VERSION ""

NS_ :

BS_:

BU_: XXX

BO_ 380 ENGINE: 8 XXX
 SG_ NEW_SIGNAL_2 : 61|2@0+ (1,0) [0|3] "" XXX
 SG_ ENGINE_RPM : 23|16@0+ (1,0) [0|255] "" XXX

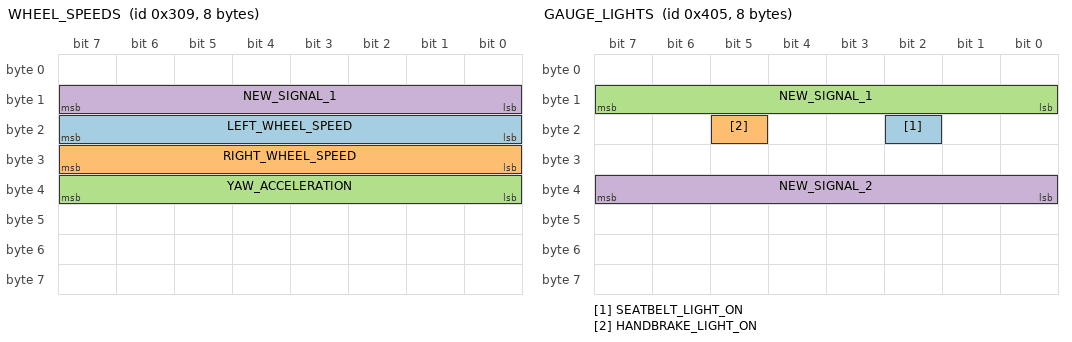
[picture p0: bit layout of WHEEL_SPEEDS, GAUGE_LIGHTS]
BO_ 777 WHEEL_SPEEDS: 8 XXX
 SG_ LEFT_WHEEL_SPEED : 23|8@0+ (1,0) [0|255] "" XXX
 SG_ RIGHT_WHEEL_SPEED : 31|8@0+ (1,0) [0|255] "" XXX
 SG_ YAW_ACCELERATION : 39|8@0+ (1,0) [0|255] "" XXX
 SG_ NEW_SIGNAL_1 : 15|8@0+ (1,0) [0|255] "" XXX

BO_ 398 NEW_MSG_2: 8 XXX
 SG_ NEW_SIGNAL_1 : 14|7@0+ (1,0) [0|255] "" XXX
 SG_ NEW_SIGNAL_2 : 21|6@0+ (1,0) [0|255] "" XXX

BO_ 1029 GAUGE_LIGHTS: 8 XXX
 SG_ SEATBELT_LIGHT_ON : 18|1@0+ (1,0) [0|255] "" XXX
 SG_ HANDBRAKE_LIGHT_ON : 21|1@0+ (1,0) [0|3] "" XXX
 SG_ NEW_SIGNAL_1 : 15|8@0+ (1,0) [0|255] "" XXX
 SG_ NEW_SIGNAL_2 : 39|8@0+ (1,0) [0|255] "" XXX

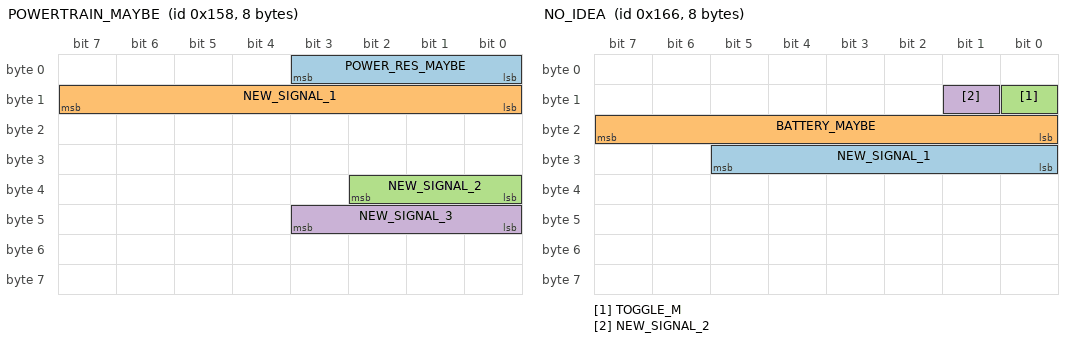
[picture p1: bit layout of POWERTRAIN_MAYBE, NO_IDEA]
BO_ 344 POWERTRAIN_MAYBE: 8 XXX
 SG_ POWER_RES_MAYBE : 0|4@1+ (1,0) [0|15] "" XXX
 SG_ NEW_SIGNAL_1 : 15|8@0+ (1,0) [0|255] "" XXX
 SG_ NEW_SIGNAL_2 : 32|3@1+ (1,0) [0|7] "" XXX
 SG_ NEW_SIGNAL_3 : 43|4@0+ (1,0) [0|255] "" XXX

BO_ 358 NO_IDEA: 8 XXX
 SG_ NEW_SIGNAL_1 : 29|6@0+ (1,0) [0|63] "" XXX
 SG_ BATTERY_MAYBE : 23|8@0+ (1,0) [0|255] "" XXX
 SG_ TOGGLE_M : 8|1@0+ (1,0) [0|255] "" XXX
 SG_ NEW_SIGNAL_2 : 9|1@1+ (1,0) [0|3] "" XXX

BO_ 401 NEW_MSG_1: 8 XXX
 SG_ NEW_SIGNAL_1 : 16|2@1+ (1,0) [0|3] "" XXX
 SG_ NEW_SIGNAL_2 : 55|8@0+ (1,0) [0|255] "" XXX

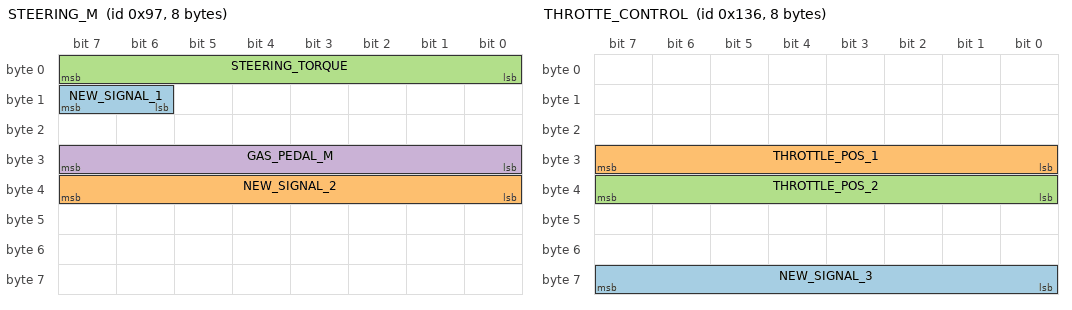
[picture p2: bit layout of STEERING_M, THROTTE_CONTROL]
BO_ 151 STEERING_M: 8 XXX
 SG_ NEW_SIGNAL_1 : 15|2@0+ (1,0) [0|255] "" XXX
 SG_ NEW_SIGNAL_2 : 39|8@0+ (1,0) [0|255] "" XXX
 SG_ STEERING_TORQUE : 7|8@0+ (1,0) [0|255] "" XXX
 SG_ GAS_PEDAL_M : 31|8@0+ (1,0) [0|255] "" XXX

BO_ 310 THROTTE_CONTROL: 8 XXX
 SG_ NEW_SIGNAL_3 : 63|8@0+ (1,0) [0|255] "" XXX
 SG_ THROTTLE_POS_1 : 31|8@0+ (1,0) [0|255] "" XXX
 SG_ THROTTLE_POS_2 : 39|8@0+ (1,0) [0|255] "" XXX

BO_ 57 NEW_MSG_3: 8 XXX
 SG_ NEW_SIGNAL_1 : 15|8@0+ (1,0) [0|255] "" XXX

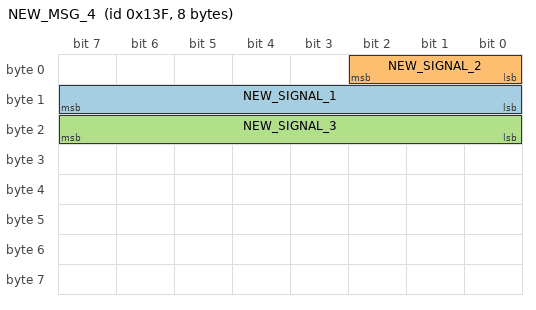
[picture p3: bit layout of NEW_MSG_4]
BO_ 319 NEW_MSG_4: 8 XXX
 SG_ NEW_SIGNAL_1 : 15|8@0+ (1,0) [0|255] "" XXX
 SG_ NEW_SIGNAL_2 : 0|3@1+ (1,0) [0|3] "" XXX
 SG_ NEW_SIGNAL_3 : 23|8@0+ (1,0) [0|255] "" XXX

BO_ 314 NEW_MSG_5: 8 XXX
 SG_ NEW_SIGNAL_1 : 15|8@0+ (1,0) [0|255] "" XXX
 SG_ NEW_SIGNAL_2 : 23|8@0+ (1,0) [0|255] "" XXX

BO_ 464 NEW_MSG_6: 8 XXX
 SG_ NEW_SIGNAL_1 : 39|8@0+ (1,0) [0|255] "" XXX
